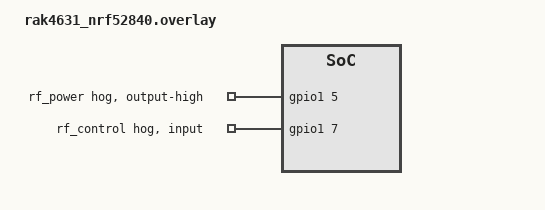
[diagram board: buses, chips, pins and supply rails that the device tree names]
/* SPDX-FileCopyrightText: Copyright (c) 2026 RAKwireless */
/* SPDX-License-Identifier: Apache-2.0 */

#include <zephyr/dt-bindings/usp/sx126x.h>

/ {
	chosen {
		zephyr,lorawan-transceiver = &lora;
	};
};

&lora {
	compatible = "semtech,sx1262-new";
	/delete-property/ rx-enable-gpios;
	/delete-property/ dio2-tx-enable;
	/delete-property/ dio3-tcxo-voltage;
	/delete-property/ tcxo-power-startup-delay-ms;
	reg = <0>;
	reset-gpios = <&gpio1 6 GPIO_ACTIVE_LOW>;
	busy-gpios = <&gpio1 14 GPIO_ACTIVE_HIGH>;
	dio1-gpios = <&gpio1 15 (GPIO_ACTIVE_HIGH | GPIO_PULL_DOWN)>;
	dio2-as-rf-switch;
	dio3-as-tcxo-control;
	tcxo-voltage = <SX126X_TCXO_SUPPLY_3_3V>;
	tcxo-wakeup-time = <5>;
	reg-mode = <SX126X_REG_MODE_DCDC>;
	/* SX1262 PA table, one entry per dBm from -9 to 22. */
	tx-power-cfg = <(1) 0x01 0x01>,
		       <(4) 0x00 0x01>,
		       <(4) 0x01 0x01>,
		       <(7) 0x00 0x01>,
		       <(2) 0x00 0x02>,
		       <(7) 0x03 0x01>,
		       <(8) 0x03 0x01>,
		       <(9) 0x03 0x01>,
		       <(13) 0x00 0x01>,
		       <(16) 0x00 0x01>,
		       <(19) 0x00 0x01>,
		       <(20) 0x00 0x01>,
		       <(18) 0x03 0x01>,
		       <(21) 0x00 0x01>,
		       <(16) 0x00 0x02>,
		       <(22) 0x00 0x01>,
		       <(22) 0x01 0x01>,
		       <(22) 0x02 0x01>,
		       <(22) 0x03 0x01>,
		       <(22) 0x04 0x01>,
		       <(22) 0x00 0x02>,
		       <(22) 0x01 0x02>,
		       <(22) 0x02 0x02>,
		       <(22) 0x03 0x02>,
		       <(22) 0x01 0x03>,
		       <(22) 0x02 0x03>,
		       <(22) 0x00 0x05>,
		       <(22) 0x01 0x05>,
		       <(22) 0x02 0x05>,
		       <(22) 0x03 0x06>,
		       <(22) 0x04 0x06>,
		       <(22) 0x04 0x07>;
	spi-max-frequency = <1000000>;
};

&gpio1 {
	rf_power: rf-power {
		gpio-hog;
		gpios = <5 GPIO_ACTIVE_HIGH>;
		output-high;
	};

	rf_control: rf-control {
		gpio-hog;
		gpios = <7 GPIO_ACTIVE_HIGH>;
		input;
	};
};
